# NEON_CM register map
Vendor: Texas Instruments
Peripheral module from a debugger description file (folder omap34xx).
Registers are 32-bit, read-only, reset 0x1 unless marked. A register's access mark holds for its fields unless they carry their own. Offsets are as the file gives them; lines under a group give offsets from that group; [hi:lo] are bit positions; {n}, {i} and the like mark numbered series; 'fields as' and 'values as' point back to an identical list; <NAME> marks a mode.

## NEON_CM
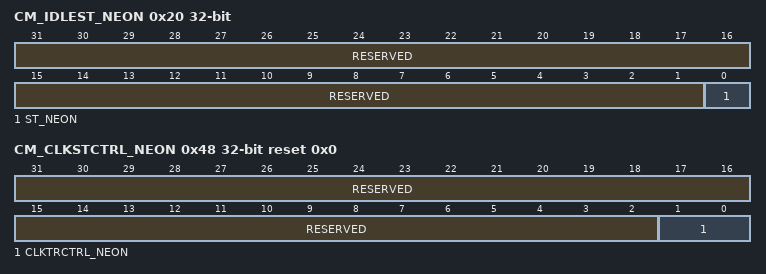
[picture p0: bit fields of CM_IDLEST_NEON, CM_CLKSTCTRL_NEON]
0x20 CM_IDLEST_NEON — Modules access availability monitoring. This register is read only and automatically updated.
  [31:1] RESERVED — Read returns 0.
  [0] ST_NEON — NEON standby status.
    0=NEON is active; 1=NEON is in standby mode
0x48 CM_CLKSTCTRL_NEON access per field reset 0x0 — This register enables the domain power state transition. It controls the HW supervised domain power state transition between ACTIVE and INACTIVE states.
  [31:2] RESERVED ro — Write 0s for future compatibility. Read returns 0.
  [1:0] CLKTRCTRL_NEON rw — Controls the clock state transition of the NEON clock domain.
    0=Automatic transition is disabled; 1=Start a software supervised sleep transition on the domain; 2=Start a software supervised wake-up transition on the domain; 3=Automatic transition is enabled. Transition is supervised by the HardWare.
